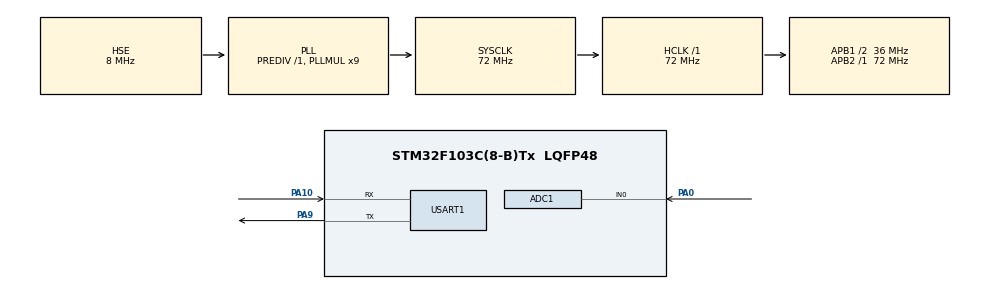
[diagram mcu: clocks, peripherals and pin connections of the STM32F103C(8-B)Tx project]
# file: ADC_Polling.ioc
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ADC1.Channel-0\#ChannelRegularConversion=ADC_CHANNEL_0
ADC1.NbrOfConversionFlag=1
ADC1.Rank-0\#ChannelRegularConversion=1
ADC1.SamplingTime-0\#ChannelRegularConversion=ADC_SAMPLETIME_1CYCLE_5
ADC1.master=1
Mcu.Family=STM32F1
Mcu.Name=STM32F103C(8-B)Tx
Mcu.Package=LQFP48
NVIC.PriorityGroup=NVIC_PRIORITYGROUP_4
PA0-WKUP.Signal=ADCx_IN0
PA10.Mode=Asynchronous
PA10.Signal=USART1_RX
PA13.Mode=Serial_Wire
PA13.Signal=SYS_JTMS-SWDIO
PA14.Mode=Serial_Wire
PA14.Signal=SYS_JTCK-SWCLK
PA9.Mode=Asynchronous
PA9.Signal=USART1_TX
PD0-OSC_IN.Mode=HSE-External-Oscillator
PD0-OSC_IN.Signal=RCC_OSC_IN
PD1-OSC_OUT.Mode=HSE-External-Oscillator
PD1-OSC_OUT.Signal=RCC_OSC_OUT
ProjectManager.HeapSize=0x200
ProjectManager.StackSize=0x400
ProjectManager.TargetToolchain=STM32CubeIDE
RCC.ADCPresc=RCC_ADCPCLK2_DIV6
RCC.AHBFreq_Value=72000000
RCC.APB1CLKDivider=RCC_HCLK_DIV2
RCC.APB1Freq_Value=36000000
RCC.APB1TimFreq_Value=72000000
RCC.APB2Freq_Value=72000000
RCC.APB2TimFreq_Value=72000000
RCC.HCLKFreq_Value=72000000
RCC.PLLMUL=RCC_PLL_MUL9
RCC.PLLSourceVirtual=RCC_PLLSOURCE_HSE
RCC.SYSCLKFreq_VALUE=72000000
RCC.SYSCLKSource=RCC_SYSCLKSOURCE_PLLCLK
RCC.USBFreq_Value=72000000
SH.ADCx_IN0.0=ADC1_IN0,IN0
USART1.VirtualMode=VM_ASYNC
board=custom

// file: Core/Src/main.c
/* USER CODE BEGIN Header */
/**
  ******************************************************************************
  * @file           : main.c
  * @brief          : Main program body
  ******************************************************************************
  * @attention
  *
  * Copyright (c) 2025 STMicroelectronics.
  * All rights reserved.
  *
  * This software is licensed under terms that can be found in the LICENSE file
  * in the root directory of this software component.
  * If no LICENSE file comes with this software, it is provided AS-IS.
  *
  ******************************************************************************
  */
/* USER CODE END Header */
#include "main.h"

/* USER CODE BEGIN Includes */
#include "stdio.h"   // Para sprintf()
#include "string.h"  // Para strlen()
/* USER CODE END Includes */

/* USER CODE BEGIN PD */
#define ADC_TIMEOUT     1000  // Timeout en ms para esperar conversión ADC
#define UART_TIMEOUT    1000  // Timeout en ms para transmisión UART
#define SAMPLE_DELAY    500   // Delay entre muestras en ms
/* USER CODE END PD */

ADC_HandleTypeDef hadc1;

UART_HandleTypeDef huart1;

/* USER CODE BEGIN PV */

uint32_t ADC_VAL;    // Variable para almacenar el valor digital del ADC (0-4095)
char buffer[15];     // Buffer para formatear la cadena a transmitir por UART

/* USER CODE END PV */

void SystemClock_Config(void);
static void MX_GPIO_Init(void);
static void MX_ADC1_Init(void);
static void MX_USART1_UART_Init(void);

int main(void)
{

  /* MCU Configuration--------------------------------------------------------*/

  /* Reset of all peripherals, Initializes the Flash interface and the Systick. */
  HAL_Init();

  /* Configure the system clock */
  SystemClock_Config();

  /* Initialize all configured peripherals */
  MX_GPIO_Init();
  MX_ADC1_Init();
  MX_USART1_UART_Init();

  /* Infinite loop */
  /* USER CODE BEGIN WHILE */
  while (1)
  {

	/* ========== PASO 1: Iniciar conversión ADC ========== */
	HAL_ADC_Start(&hadc1);

	/* ========== PASO 2: Esperar a que finalice la conversión (Polling) ========== */
	/**
	* HAL_ADC_PollForConversion():
	* - Espera activamente (bloqueante) hasta que la conversión finalice
	* - Parámetros:
	*   &hadc1: Manejador del ADC
	*   ADC_TIMEOUT: Tiempo máximo de espera en ms
	* - Retorna HAL_OK si la conversión se completó exitosamente
	*
	* NOTA: Durante esta espera el CPU está ocupado y no puede realizar
	* otras tareas. Por eso se llama "modo bloqueante".
	*/
	if(HAL_ADC_PollForConversion(&hadc1, ADC_TIMEOUT) == HAL_OK)
	{
		/* ========== PASO 3: Leer el valor convertido ========== */
		/**
		* HAL_ADC_GetValue():
		* - Lee el resultado de la conversión del registro de datos del ADC
		* - Retorna un valor de 12 bits (0 - 4095) para este microcontrolador
		* - Fórmula de conversión a voltaje:
		*   Voltaje = (ADC_VAL / 4095) * VREF
		*   donde VREF típicamente es 3.3V
		*/
		ADC_VAL = HAL_ADC_GetValue(&hadc1);
	}

	/* ========== PASO 4: Detener el ADC ========== */
	/**
	* HAL_ADC_Stop():
	* - Detiene el periférico ADC
	* - Útil para ahorrar energía entre conversiones
	* - En aplicaciones de bajo consumo esto puede ser importante
	*/
	HAL_ADC_Stop(&hadc1);

	/* ========== PASO 5: Formatear y transmitir el resultado ========== */
	sprintf(buffer, "ADC: %lu\r\n", ADC_VAL);

	HAL_UART_Transmit(&huart1, (uint8_t*)buffer, strlen(buffer), UART_TIMEOUT);

	/* ========== PASO 6: Esperar antes de la siguiente muestra ========== */
	HAL_Delay(SAMPLE_DELAY);

    /* USER CODE END WHILE */

  }
}

void SystemClock_Config(void)
{
  RCC_OscInitTypeDef RCC_OscInitStruct = {0};
  RCC_ClkInitTypeDef RCC_ClkInitStruct = {0};
  RCC_PeriphCLKInitTypeDef PeriphClkInit = {0};

  /** Initializes the RCC Oscillators according to the specified parameters
  * in the RCC_OscInitTypeDef structure.
  */
  RCC_OscInitStruct.OscillatorType = RCC_OSCILLATORTYPE_HSE;
  RCC_OscInitStruct.HSEState = RCC_HSE_ON;
  RCC_OscInitStruct.HSEPredivValue = RCC_HSE_PREDIV_DIV1;
  RCC_OscInitStruct.HSIState = RCC_HSI_ON;
  RCC_OscInitStruct.PLL.PLLState = RCC_PLL_ON;
  RCC_OscInitStruct.PLL.PLLSource = RCC_PLLSOURCE_HSE;
  RCC_OscInitStruct.PLL.PLLMUL = RCC_PLL_MUL9;
  if (HAL_RCC_OscConfig(&RCC_OscInitStruct) != HAL_OK)
  {
    Error_Handler();
  }

  /** Initializes the CPU, AHB and APB buses clocks
  */
  RCC_ClkInitStruct.ClockType = RCC_CLOCKTYPE_HCLK|RCC_CLOCKTYPE_SYSCLK
                              |RCC_CLOCKTYPE_PCLK1|RCC_CLOCKTYPE_PCLK2;
  RCC_ClkInitStruct.SYSCLKSource = RCC_SYSCLKSOURCE_PLLCLK;
  RCC_ClkInitStruct.AHBCLKDivider = RCC_SYSCLK_DIV1;
  RCC_ClkInitStruct.APB1CLKDivider = RCC_HCLK_DIV2;
  RCC_ClkInitStruct.APB2CLKDivider = RCC_HCLK_DIV1;

  if (HAL_RCC_ClockConfig(&RCC_ClkInitStruct, FLASH_LATENCY_2) != HAL_OK)
  {
    Error_Handler();
  }
  PeriphClkInit.PeriphClockSelection = RCC_PERIPHCLK_ADC;
  PeriphClkInit.AdcClockSelection = RCC_ADCPCLK2_DIV6;
  if (HAL_RCCEx_PeriphCLKConfig(&PeriphClkInit) != HAL_OK)
  {
    Error_Handler();
  }
}

static void MX_ADC1_Init(void)
{

  ADC_ChannelConfTypeDef sConfig = {0};

  /** Common config
  */
  hadc1.Instance = ADC1;
  hadc1.Init.ScanConvMode = ADC_SCAN_DISABLE;
  hadc1.Init.ContinuousConvMode = DISABLE;
  hadc1.Init.DiscontinuousConvMode = DISABLE;
  hadc1.Init.ExternalTrigConv = ADC_SOFTWARE_START;
  hadc1.Init.DataAlign = ADC_DATAALIGN_RIGHT;
  hadc1.Init.NbrOfConversion = 1;
  if (HAL_ADC_Init(&hadc1) != HAL_OK)
  {
    Error_Handler();
  }

  /** Configure Regular Channel
  */
  sConfig.Channel = ADC_CHANNEL_0;
  sConfig.Rank = ADC_REGULAR_RANK_1;
  sConfig.SamplingTime = ADC_SAMPLETIME_1CYCLE_5;
  if (HAL_ADC_ConfigChannel(&hadc1, &sConfig) != HAL_OK)
  {
    Error_Handler();
  }

}

static void MX_USART1_UART_Init(void)
{

  huart1.Instance = USART1;
  huart1.Init.BaudRate = 115200;
  huart1.Init.WordLength = UART_WORDLENGTH_8B;
  huart1.Init.StopBits = UART_STOPBITS_1;
  huart1.Init.Parity = UART_PARITY_NONE;
  huart1.Init.Mode = UART_MODE_TX_RX;
  huart1.Init.HwFlowCtl = UART_HWCONTROL_NONE;
  huart1.Init.OverSampling = UART_OVERSAMPLING_16;
  if (HAL_UART_Init(&huart1) != HAL_OK)
  {
    Error_Handler();
  }

}

static void MX_GPIO_Init(void)
{

  /* GPIO Ports Clock Enable */
  __HAL_RCC_GPIOD_CLK_ENABLE();
  __HAL_RCC_GPIOA_CLK_ENABLE();

}

void Error_Handler(void)
{
  __disable_irq();
  while (1)
  {
  }
}
